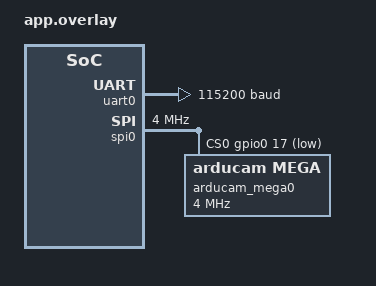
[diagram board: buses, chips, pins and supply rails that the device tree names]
/**
 * The MIT License (MIT)
 *
 * Copyright 2021 Arducam Technology co., Ltd. All Rights Reserved.
 *
 * Permission is hereby granted, free of charge, to any person obtaining a copy
 * of this software and associated documentation files (the "Software"), to deal
 * in the Software without restriction, including without limitation the rights
 * to use, copy, modify, merge, publish, distribute, sublicense, and/or sell
 * copies of the Software, and to permit persons to whom the Software is
 * furnished to do so, subject to the following conditions:
 *
 * The above copyright notice and this permission notice shall be included in
 * all copies or substantial portions of the Software.
 *
 * THE SOFTWARE IS PROVIDED "AS IS", WITHOUT WARRANTY OF ANY KIND, EXPRESS OR
 * IMPLIED, INCLUDING BUT NOT LIMITED TO THE WARRANTIES OF MERCHANTABILITY,
 * FITNESS FOR A PARTICULAR PURPOSE AND NONINFRINGEMENT. IN NO EVENT SHALL THE
 * AUTHORS OR COPYRIGHT HOLDERS BE LIABLE FOR ANY CLAIM, DAMAGES OR OTHER
 * LIABILITY, WHETHER IN AN ACTION OF CONTRACT, TORT OR OTHERWISE, ARISING FROM,
 * OUT OF OR IN CONNECTION WITH THE SOFTWARE OR THE USE OR OTHER DEALINGS IN
 * THE SOFTWARE
 *
 * Application overlay for testing driver builds
 *
 * Names in this file should be chosen in a way that won't conflict
 * with real-world devicetree nodes, to allow these tests to run on
 * (and be extended to test) real hardware.
 */

&uart0{
	current-speed = <115200>;
};

&spi0 {
	clock-frequency = <4000000>;
	cs-gpios = <&gpio0 17 GPIO_ACTIVE_LOW>;
	pinctrl-names = "default";
	arducam_mega0:arducam-mega0@0 {
		compatible = "arducam,mega";
		reg = <0>;
		spi-max-frequency = <4000000>;
		status = "okay";
	};
};

